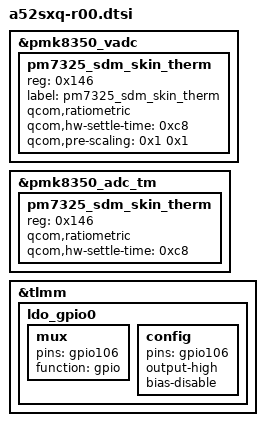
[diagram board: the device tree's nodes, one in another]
// SPDX-License-Identifier: GPL-2.0
/*
 * a52sxq board description for the Qualcomm 6.12 yupik base: what only hardware-revision entry r00 has
 * GENERATED by tools/gen.py from the phone's stock dtbo (5.4 bindings, values verbatim).
 * Do not edit: hand-written 6.12 changes live in a52sxq-bsp612-fixups.dtsi.
 */

&pmk8350_vadc {

	pm7325_sdm_skin_therm {
		reg = <0x146>;
		label = "pm7325_sdm_skin_therm";
		qcom,ratiometric;
		qcom,hw-settle-time = <0xc8>;
		qcom,pre-scaling = <0x1 0x1>;
	};
};

&pmk8350_adc_tm {

	pm7325_sdm_skin_therm {
		reg = <0x146>;
		qcom,ratiometric;
		qcom,hw-settle-time = <0xc8>;
	};
};

&tlmm {

	ldo_gpio0: ldo_gpio0 {

		mux {
			pins = "gpio106";
			function = "gpio";
		};

		config {
			pins = "gpio106";
			output-high;
			bias-disable;
		};
	};
};

